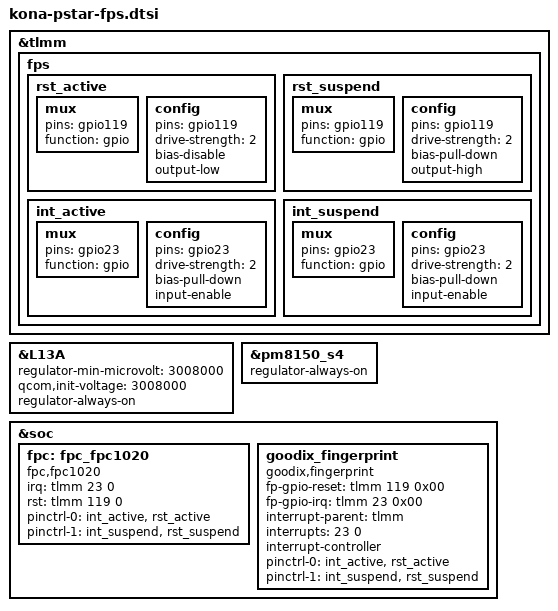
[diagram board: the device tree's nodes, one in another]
#include <dt-bindings/regulator/qcom,rpmh-regulator-levels.h>
&tlmm {

	fps {
		rst_active: rst_active {
			/* RESET */
			mux {
				pins = "gpio119";
				function = "gpio";
			};
			config {
				pins = "gpio119";
				drive-strength = <2>; /* 2 MA */
				bias-disable;
				output-low;
			};
		};

		rst_suspend: rst_suspend{
			/* RESET */
			mux {
				pins = "gpio119";
				function = "gpio";
			};

			config {
				pins = "gpio119";
				drive-strength = <2>; /* 2 MA */
				bias-pull-down; /* pull down */
				output-high;
			};
		};

		int_active: int_active {
			/* INTERRUPT */
			mux {
				pins = "gpio23";
				function = "gpio";
			};

			config {
				pins = "gpio23";
				drive-strength = <2>; /* 2 MA */
				bias-pull-down; /* pull down */
				input-enable;
			};
		};

		int_suspend: int_suspend{
			/* INTERRUPT */
			mux {
				pins = "gpio23";
				function = "gpio";
			};

			config {
				pins = "gpio23";
				drive-strength = <2>; /* 2 MA */
				bias-pull-down; /* pull down */
				input-enable;
			};
		};
	};
};

/* Goodix3626z9&FPC1542 AVDD L13A 3p0v */
&L13A {
	regulator-min-microvolt = <3008000>;
	qcom,init-voltage = <3008000>;
	/* qcom,init-mode = <RPMH_REGULATOR_MODE_HPM>;*/
	regulator-always-on;
};

/* legacy FPC VDD S4A 1p8v */
&pm8150_s4 {
	regulator-always-on;
};

&soc {

	fpc: fpc_fpc1020 {
		compatible = "fpc,fpc1020";
		status = "ok";
		irq = <&tlmm 23 0>;
		rst = <&tlmm 119 0>;
		pinctrl-names = "default", "suspend";
		pinctrl-0 = <&int_active &rst_active>;
		pinctrl-1 = < &int_suspend &rst_suspend>;
	};

	goodix_fingerprint{
		status = "ok";
		compatible = "goodix,fingerprint";
		fp-gpio-reset = <&tlmm 119 0x00>;
		fp-gpio-irq = <&tlmm 23  0x00>;
		interrupt-parent = <&tlmm>;
		interrupts = <23 0>;
		interrupt-controller;
		pinctrl-names = "default", "suspend";
		pinctrl-0 = <&int_active &rst_active>;
		pinctrl-1 = <&int_suspend &rst_suspend>;
	};
};
